# lpc1788 register map
File version: 0.7
LPC178x/LPC177x M3
CPU: CM3 r0p0, little endian, MPU, no FPU, 3 interrupt priority bits
Registers are 32-bit, read-write, reset 0x0 unless marked. A register's access mark holds for its fields unless they carry their own. Offsets are from the block's base; lines under a group give offsets from that group; [hi:lo] are bit positions; {n}, {i} and the like mark numbered series; 'fields as' and 'values as' point back to an identical list; <NAME> marks a mode.

## Memory map
0x00200000 FLASHCTRL size 0xFFF — Flash control block
0x20080000 GPDMA size 0xFFF — General purpose DMA controller
0x20084000 ETHERNET size 0xFFF
0x20088000 LCD size 0xFFF — LCD controller
0x2008C000 USB size 0xFFF — USB device/host/OTG controller
0x20090000 CRC size 0xFFF — CRC engine
0x20098000 GPIO0 size 0xFFF — General Purpose I/O
0x20098020 GPIO1 size 0xFFF
0x20098040 GPIO2 size 0xFFF
0x20098060 GPIO3 size 0xFFF
0x20098080 GPIO4 size 0xFFF
0x200980A0 GPIO5 size 0xFFF
0x2009C000 EMC size 0xFFF — ExternalMemory Controller (EMC)
0x40000000 WWDT size 0xFFF — Windowed Watchdog Timer (WWDT)
0x40004000 TIMER0 size 0xFFF — Timer0/1/2/3
0x40008000 TIMER1 size 0xFFF
0x4000C000 UART0 size 0xFFF — UART0/2/3
0x40010000 UART1 size 0xFFF
0x40014000 PWM0 size 0xFFF — Pulse Width Modulators (PWM0/1)
0x40018000 PWM1 size 0xFFF
0x4001C000 I2C0 size 0xFFF — I2C bus interface
0x40024000 RTC size 0xFFF — Real Time Clock (RTC)
0x40028080 GPIOINT size 0xFFF — GPIO
0x4002C000 IOCON size 0xFFF — IOCON pin configuration
0x40030000 SSP1 size 0xFFF — SSP1 controller
0x40034000 ADC size 0xFFF — Analog-to-Digital Converter (ADC)
0x40038000 CANAFRAM size 0xFFF — CAN acceptance filter RAM
0x4003C000 CANAF size 0xFFF — CAN controller acceptance filter
0x40040000 CCAN size 0xFFF — Central CAN controller
0x40044000 CAN1 size 0xFFF — CAN1 controller
0x40048000 CAN2 size 0xFFF
0x4005C000 I2C1 size 0xFFF
0x40088000 SSP0 size 0x300 — SSP controller
0x4008C000 DAC size 0xFFF — Digital-to-Analog Converter (DAC)
0x40090000 TIMER2 size 0xFFF
0x40094000 TIMER3 size 0xFFF
0x40098000 UART2 size 0xFFF
0x4009C000 UART3 size 0xFFF
0x400A0000 I2C2 size 0xFFF
0x400A4000 UART4 size 0xFFF
0x400A8000 I2S size 0xFFF — I2S interface
0x400AC000 SSP2 size 0x300
0x400B8000 MCPWM size 0xFFF — Motor Control PWM
0x400BC000 QEI size 0xFFF — Quadrature Encoder Interface (QEI)
0x400C0000 SDMMC size 0xFFFF — SD card interface
0x400FC000 SYSCON size 0xFFF — System and clock control

## Interrupts
0 WWDT
1 TIMER0
2 TIMER1
3 TIMER2
4 TIMER3
5 UART0
6 UART1
7 UART2
8 UART3
9 PWM1
10 I2C0
11 I2C1
12 I2C2
14 SSP0
15 SSP1
17 RTC
18 EINT0 (SYSCON)
19 EINT1 (SYSCON)
20 EINT2 (SYSCON)
21 EINT3 (SYSCON)
22 ADC
23 BOD (SYSCON)
24 USB
25 CAN (CAN1)
26 GPDMA
27 I2S
28 ETHERNET
29 SDMMC
30 MCPWM
31 QEI
33 USB_NEED_CLK (USB)
35 UART4
36 SSP2
37 LCD
38 GPIOINT
39 PWM0
40 EEPROM (FLASHCTRL)

## CRC — CRC engine
Base 0x20090000
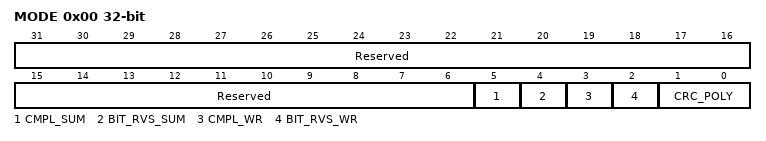
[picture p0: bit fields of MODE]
0x00 MODE — CRC mode register
  [31:6] Reserved — Always 0 when read
  [5] CMPL_SUM — Select one's complement for CRC_SUM
    0=NO_ONES_COMPLEMENT_ (No one's complement for CRC_SUM); 1=ONES_COMPLEMENT_FOR (One's complement for CRC_SUM)
  [4] BIT_RVS_SUM — Select bit order revers for CRC_SUM
    0=NO_BIT_ORDER_REVERSE (No bit order reverse for CRC_SUM); 1=BIT_ORDER_REVERSE_FO (Bit order reverse for CRC_SUM)
  [3] CMPL_WR — Select one's complement for CRC_WR_DATA
    0=NO_ONES_COMPLEMENT_ (No one's complement for CRC_WR_DATA); 1=ONES_COMPLEMENT_FOR (One's complement for CRC_WR_DATA)
  [2] BIT_RVS_WR — Select bit order for CRC_WR_DATA
    0=NO_BIT_ORDER_REVERSE (No bit order reverse for CRC_WR_DATA (per byte)); 1=BIT_ORDER_REVERSE_FO (Bit order reverse for CRC_WR_DATA (per byte))
  [1:0] CRC_POLY — Select CRC polynomial
    0=CRC_CCITT_POLYNOMIAL; 1=CRC_16_POLYNOMIAL; 2=CRC_32_POLYNOMIAL
0x04 SEED reset 0xFFFF — CRC seed register
  [31:0] CRC_SEED — A write access to this register will load CRC seed value to CRC_SUM register with selected bit order and 1's complement pre-processes. A write access to this register will overrule the CRC calculation in progresses.
0x08 SUM ro reset 0xFFFF — CRC checksum register
  [31:0] CRC_SUM — The most recent CRC sum can be read through this register with selected bit order and 1's complement post-processes.
0x08 DATA wo reset not defined — CRC data register
  [31:0] CRC_WR_DATA — Data written to this register will be taken to perform CRC calculation with selected bit order and 1's complement pre-process. Any write size 8, 16 or 32-bit are allowed and accept back-to-back transactions.
